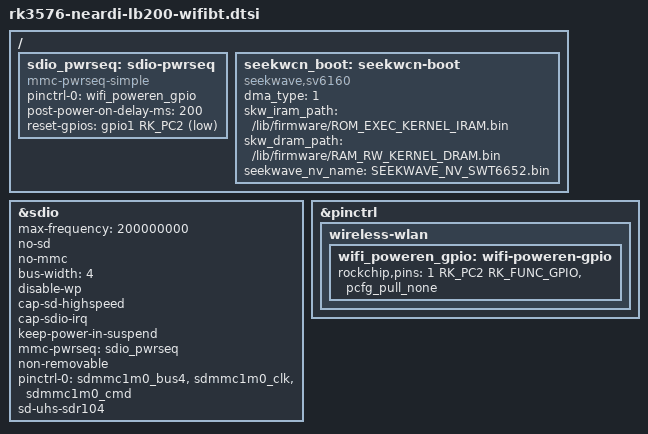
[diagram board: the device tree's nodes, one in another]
// SPDX-License-Identifier: (GPL-2.0+ OR MIT)
/*
 * Neardi LB200 Seekwave SDIO WiFi
 */

#include <dt-bindings/gpio/gpio.h>
#include <dt-bindings/pinctrl/rockchip.h>

/ {
	sdio_pwrseq: sdio-pwrseq {
		compatible = "mmc-pwrseq-simple";
		pinctrl-names = "default";
		pinctrl-0 = <&wifi_poweren_gpio>;
		post-power-on-delay-ms = <200>;
		reset-gpios = <&gpio1 RK_PC2 GPIO_ACTIVE_LOW>;
	};

	seekwcn_boot: seekwcn-boot {
		compatible = "seekwave,sv6160";
		dma_type = <1>;
		skw_iram_path = "/lib/firmware/ROM_EXEC_KERNEL_IRAM.bin";
		skw_dram_path = "/lib/firmware/RAM_RW_KERNEL_DRAM.bin";
		seekwave_nv_name = "SEEKWAVE_NV_SWT6652.bin";
		status = "okay";
	};
};

&sdio {
	max-frequency = <200000000>;
	no-sd;
	no-mmc;
	bus-width = <4>;
	disable-wp;
	cap-sd-highspeed;
	cap-sdio-irq;
	keep-power-in-suspend;
	mmc-pwrseq = <&sdio_pwrseq>;
	non-removable;
	pinctrl-names = "default";
	pinctrl-0 = <&sdmmc1m0_bus4 &sdmmc1m0_clk &sdmmc1m0_cmd>;
	sd-uhs-sdr104;
	status = "okay";
};

&pinctrl {
	wireless-wlan {
		wifi_poweren_gpio: wifi-poweren-gpio {
			rockchip,pins = <1 RK_PC2 RK_FUNC_GPIO &pcfg_pull_none>;
		};
	};
};
